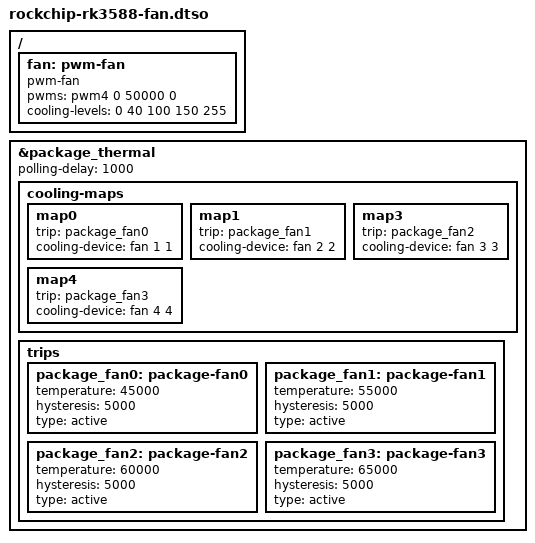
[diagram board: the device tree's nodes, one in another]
// SPDX-License-Identifier: (GPL-2.0+ OR MIT)
/dts-v1/;
/plugin/;

/ {
    fragment@0 {
        target-path = "/";

        __overlay__ {
			fan: pwm-fan {
				compatible = "pwm-fan";
				#cooling-cells = <2>;
				pwms = <&pwm4 0 50000 0>;
				cooling-levels = <0 40 100 150 255>;
			};
        };
    };

	fragment@1 {
		target = <&package_thermal>;

		__overlay__ {
			polling-delay = <1000>;
			cooling-maps {
				map0 {
					trip = <&package_fan0>;
					cooling-device = <&fan 1 1>;
				};

				map1 {
					trip = <&package_fan1>;
					cooling-device = <&fan 2 2>;
				};

				map3 {
					trip = <&package_fan2>;
					cooling-device = <&fan 3 3>;
				};

				map4 {
					trip = <&package_fan3>;
					cooling-device = <&fan 4 4>;
				};
			};

			trips {
				package_fan0: package-fan0 {
					temperature = <45000>;
					hysteresis = <5000>;
					type = "active";
				};

				package_fan1: package-fan1 {
					temperature = <55000>;
					hysteresis = <5000>;
					type = "active";
				};

				package_fan2: package-fan2 {
					temperature = <60000>;
					hysteresis = <5000>;
					type = "active";
				};

				package_fan3: package-fan3 {
					temperature = <65000>;
					hysteresis = <5000>;
					type = "active";
				};
			};
		};
	};
};
